# RL6842_IP_SVD register map
Vendor: Realtek
Registers are 32-bit, read-write, reset 0x0 unless marked. A register's access mark holds for its fields unless they carry their own. Offsets are from the block's base; [hi:lo] are bit positions; {n}, {i} and the like mark numbered series.

## lp_pmc
Base 0x4100C300
0x00 REG_WAK_STATUS0 ro
  [31:0] wak_sta_31_0 — wak evt status. It can't be cleare here, clear at IP side . Bit0: WIFI_FISR_FESR_IRQ Bit1: WIFI_FTSR_MAILBOX_IRQ Bit2: AP_WAKE_IRQ Bit3: DSP_WAKE_IRQ Bit4: BT_WAKE_HOST Bit5: IPC_KR4 Bit6: IPC_KM4 Bit7: IPC_DSP Bit8: IWDG Bit9: Timer0 Bit10: Timer1 Bit11: Timer2 Bit12: Timer3 Bit13: Timer4 Bit14: Timer5 Bit15: Timer6 Bit16: Timer7 Bit17: UART0 Bit18: UART1 Bit19: UART2 Bit20: UART3 Bit21: UART_LOG Bit22: GPIOA Bit23: GPIOB Bit24: CTOUCH Bit25: SPI0 Bit26: SPI1 Bit27: AON_RTS Bit28: ADC Bit29: ADC_COMP Bit30: BOR Bit31: PWR_DOWN
0x04 REG_WAK_STATUS1 ro
  [31:0] wak_sta_63_32 — wak evt status. It can't be cleare here, clear at IP side . Bit0: AON_TIMER Bit1: AON_GPIO_WAKE Bit2: VAD Bit3~31: Reserved
0x08 REG_WAK_MASK0_NP
  [31:0] wak_np_imr_31_0 — 1:mask enable for wake NP, this used to wak pmc
0x0C REG_WAK_MASK1_NP
  [31:0] wak_np_imr_63_32 — 1:mask enable for wake NP
0x10 REG_WAK_MASK0_AP
  [31:0] wak_ap_imr_31_0 — 1:mask enable for wake AP
0x14 REG_WAK_MASK1_AP
  [31:0] wak_ap_imr_63_32 — 1:mask enable for wake AP
0x18 REG_WAK_MASK0_DSP
  [31:0] wak_dsp_imr_31_0 — 1:mask enable for wake DSP
0x1C REG_WAK_MASK1_DSP
  [31:0] wak_dsp_imr_63_32 — 1:mask enable for wake DSP
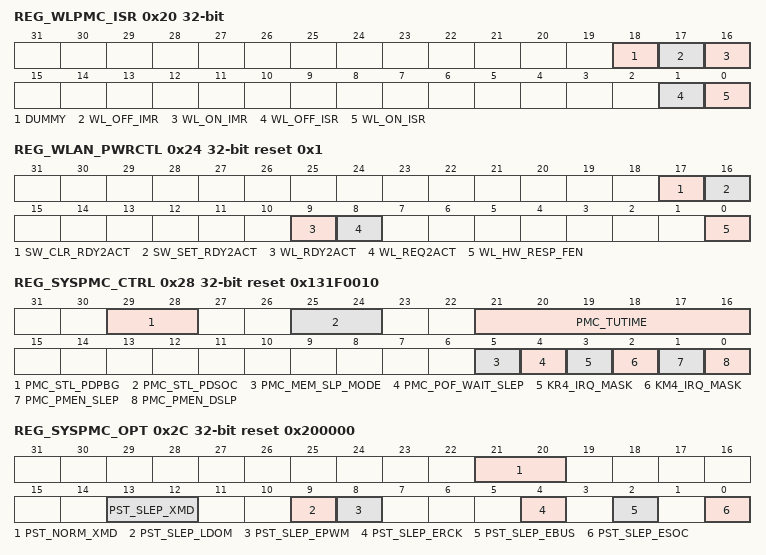
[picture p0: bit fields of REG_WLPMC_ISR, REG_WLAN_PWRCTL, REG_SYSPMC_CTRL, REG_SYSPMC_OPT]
0x20 REG_WLPMC_ISR access per field
  [18] DUMMY rw, [17] WL_OFF_IMR rw, [16] WL_ON_IMR rw, [1] WL_OFF_ISR ro, [0] WL_ON_ISR ro
0x24 REG_WLAN_PWRCTL access per field reset 0x1
  [17] SW_CLR_RDY2ACT rw — System infrom WLAN ready to active
  [16] SW_SET_RDY2ACT rw
  [9] WL_RDY2ACT ro — System infrom WLAN ready to active
  [8] WL_REQ2ACT ro
  [0] WL_HW_RESP_FEN rw — 1: enable HW auto response
0x28 REG_SYSPMC_CTRL reset 0x131F0010
  [29:28] PMC_STL_PDPBG — timer wait for PLL bandgag power stable . Spec is 160us 00:8us * 2^4 01:8us * 2^5 10:8us * 2^6 11:8us * 2^7
  [25:24] PMC_STL_PDSOC — timer wait for core power power-cut power stable . 00:8us * 2^5 01:8us * 2^6 10:8us * 2^7 11:8us * 2^8
  [21:16] PMC_TUTIME — PMC timeunit setting, in cycles of osc4M e.g, default 0x1F, timeunit = 8us
  [5] PMC_MEM_SLP_MODE — memory power mode parameter select 1:select paramter of sleep mode 0:select paramter of normal mode
  [4] PMC_POF_WAIT_SLEP — 1.when SW set pmen_slep or pmen_dslp , hw pmc will wait km0 enter sleep mode , then begin to pof seq 0.Not wait km0 sleep
  [3] KR4_IRQ_MASK — 1.mask all KR4 interrupt 0:release all KR4 interrupt
  [2] KM4_IRQ_MASK — 1.mask all KM4 interrupt 0:release all KM4 interrupt
  [1] PMC_PMEN_SLEP — 1: Request PMC to enter sleep state, auto clear to 0 after PMC finishes
  [0] PMC_PMEN_DSLP — 1: Request PMC to enter deep-sleep state, auto clear to 0 after PMC finishes
0x2C REG_SYSPMC_OPT reset 0x200000
  [21:20] PST_NORM_XMD — Normal setting for XTAL mode selection 00: XTAL will be off when PMC resume from sleep mode 01: XTAL will be in LPS when PMC resume from sleep mode 10/11: XTAL will be in Normal when PMC resume from sleep mode
  [13:12] PST_SLEP_XMD — Sleep setting for XTAL mode selection 00: XTAL will be off when PMC enter into sleep mode 01: XTAL will be in LPS when PMC enter into sleep mode 10/11: XTAL will be in Normal when PMC enter into sleep mode
  [9] PST_SLEP_LDOM — Sleep setting for core LDO mode selection(the bit is discarded,use PST_SLEP_EPWM instead) 1: core LDO keeps at normal mode when PMC enter into sleep mode 0: core switch to standby mode when PMC enter into sleep mode
  [8] PST_SLEP_EPWM — Sleep setting for SWR mode selection 1: SWR keeps at PWM mode when PMC enter into sleep mode 0: SWR switch to PFM when PMC enter into sleep mode
  [4] PST_SLEP_ERCK — 1: Enable lpon clock when PMC enter into sleep mode 0: Gate lpon clock when PMC enter into sleep mode
  [2] PST_SLEP_EBUS — 1: Enable platform clock when PMC entro into sleep mode 0: Gate platform clock when PMC entro into sleep mode
  [0] PST_SLEP_ESOC — 1: power enable SOC platform when PMC enter into sleep mode (clock-gating) 0: power off SoC domain when PMC enter into sleep mode (power-gating)
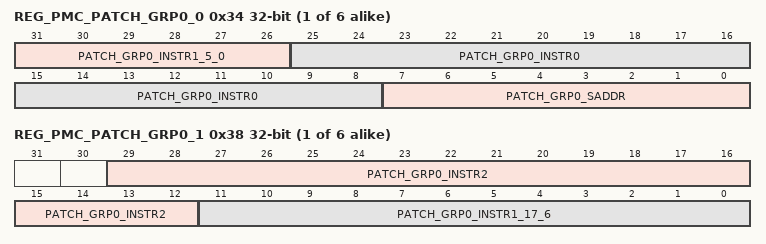
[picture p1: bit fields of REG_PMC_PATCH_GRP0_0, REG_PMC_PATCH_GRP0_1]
{0x34+8i} REG_PMC_PATCH_GRP{i}_0 (i=0..5)
  [31:26] PATCH_GRP{i}_INSTR1_5_0 — instruction1 of LSYSON PMC patch group{i},bit[5:0]
  [25:8] PATCH_GRP{i}_INSTR0 — instruction0 of LSYSON PMC patch group{i}
  [7:0] PATCH_GRP{i}_SADDR — Start address of the first instruction of LSYSON PMC patch group{i}
{0x38+8i} REG_PMC_PATCH_GRP{i}_1 (i=0..5)
  [29:12] PATCH_GRP{i}_INSTR2 — instruction2 of LSYSON PMC patch group{i}
  [11:0] PATCH_GRP{i}_INSTR1_17_6 — instruction1 of LSYSON PMC patch group{i},bit[17:6]
